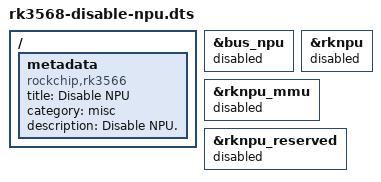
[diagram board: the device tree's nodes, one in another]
/dts-v1/;
/plugin/;

/ {
	metadata {
		title = "Disable NPU";
		compatible = "rockchip,rk3566", "rockchip,rk3568";
		category = "misc";
		description = "Disable NPU.";
	};

	fragment@0 {
		target = <&bus_npu>;

		__overlay__ {
			status = "disabled";
		};
	};

	fragment@1 {
		target = <&rknpu>;

		__overlay__ {
			status = "disabled";
		};
	};

	fragment@2 {
		target = <&rknpu_mmu>;

		__overlay__ {
			status = "disabled";
		};
	};

	fragment@3 {
		target = <&rknpu_reserved>;

		__overlay__ {
			status = "disabled";
		};
	};
};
